# CM85F register map
Registers are read-write, no defined reset value unless marked. A register's access mark holds for its fields unless they carry their own. Offsets are from the block's base; [hi:lo] are bit positions; {n}, {i} and the like mark numbered series; 'fields as' and 'values as' point back to an identical list.

## MSC — Memory System Control Registers
Base 0xE001E000
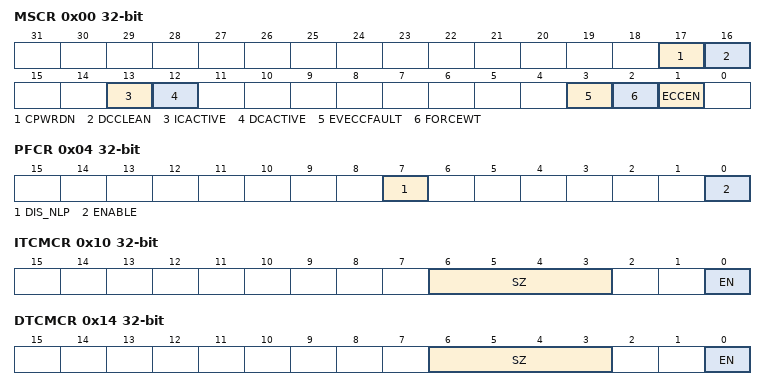
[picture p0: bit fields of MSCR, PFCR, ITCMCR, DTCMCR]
0x00 MSCR — Memory System Control Register controls the memory system features specific to the processor
  [17] CPWRDN — Indicates when the data and instruction caches are not accessible because they are either being powered down or being initialized using the automatic invalidation sequence
    0=Data and instruction cache is in normal operational state; 1=Data and instruction cacheis powered down or automatic invalidation sequence is in process
  [16] DCCLEAN — Indicates whether the data cache contains any dirty lines
    0=Level 1 (L1) data cache contains at least one dirty line; 1=L1 data cache does not contain any dirty lines
  [13] ICACTIVE — Indicates whether the L1 instruction cache is active
    0=L1 instruction cache is inactive; 1=L1 instruction cache is active
  [12] DCACTIVE — Indicates whether the L1 data cache is active
    0=L1 data cache is inactive; 1=L1 data cache is active
  [3] EVECCFAULT — Enables asynchronous BusFault exceptions when data is lost on evictions
    0=Asynchronous BusFaults are not generated when evicting lines with multi-bit errors in the data; 1=Asynchronous aborts are generated when evicting lines with multi-errors in the data
  [2] FORCEWT — Enables Forced Write-Through in the L1 data cache
    0=Force Write-Through is disabled; 1=Force Write-Through is enabled
  [1] ECCEN — Indicates whether Error Correcting Code (ECC) is present and enabled
    0=ECC not present or not enabled; 1=ECC present and enabled
0x04 PFCR — Prefetcher Control Register controls the prefetcher
  [7] DIS_NLP — Disables Next Line Prefetch mode
    0=Next Line Prefetch is enabled; 1=Next Line Prefetch is disabled
  [0] ENABLE — Prefetcher enable
    0=Prefetcher is disabled; 1=Prefetcher is enabled
0x10 ITCMCR — ITCM Control Register enable access to the Tightly Coupled Memories (TCMs) by software running on the processor
  [6:3] SZ — Indicates the size of the relevant TCM
    0=No TCM implemented; 3=4KB; 4=8KB; 5=16KB; 6=32KB; 7=64KB; 8=128KB; 9=256KB; 10=512KB; 11=1MB; 12=2MB; 13=4MB; 14=8MB; 15=16MB
  [0] EN — TCM enable
    0=TCM disabled; 1=TCM enabled
0x14 DTCMCR — DTCM Control Register enable access to the Tightly Coupled Memories (TCMs) by software running on the processor
  fields as ITCMCR
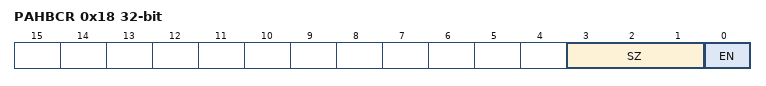
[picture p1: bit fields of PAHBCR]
0x18 PAHBCR — P-AHB Control Register enables accesses to Peripheral AHB (P-AHB) interface from software running on the processor
  [3:1] SZ — P-AHB size
    0=0MB. This implies that P-AHB disabled.; 1=64MB; 2=128MB; 3=256MB; 4=512MB
  [0] EN — P-AHB enable
    0=P-AHB disabled; 1=P-AHB enabled

## DCA — Direct Cache Access
Base 0xE001E200
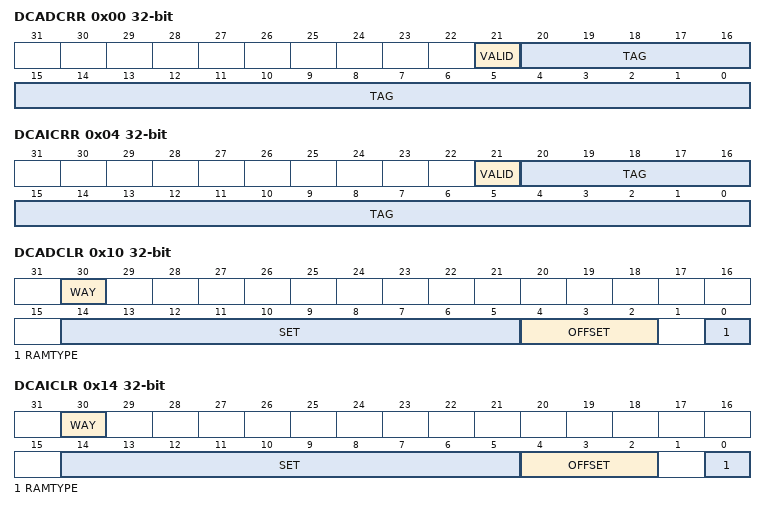
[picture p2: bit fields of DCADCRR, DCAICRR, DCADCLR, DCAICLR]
0x00 DCADCRR ro — Direct Data Cache Access Read Registers read the data from the Level 1 (L1) data cache from the location that is determined by the DCADCLR registers
  [21] VALID — Valid state of the cache line
  [20:0] TAG — Tag address. The number of significant bits of TAG depends on the cache size.
0x04 DCAICRR ro — Direct Instruction Cache Access Read Registers read the data from the Level 1 (L1) instruction cache from the location that is determined by the DCAICLR registers
  fields as DCADCRR
0x10 DCADCLR — Direct Data Cache Access Location Registers set the location to be read from the Level 1 (L1) data cache
  [30] WAY — Cache way
  [14:5] SET — Set index. The number of significant bits of SET depends on the cache size.
  [4:2] OFFSET — Data offset
  [0] RAMTYPE
    0=Tag RAM; 1=Data RAM
0x14 DCAICLR — Direct Instruction Cache Access Location Registers set the location to be read from the Level 1 (L1) instruction cache
  fields as DCADCLR

## ERRBNK — Implementation defined error banking
Base 0xE001E100
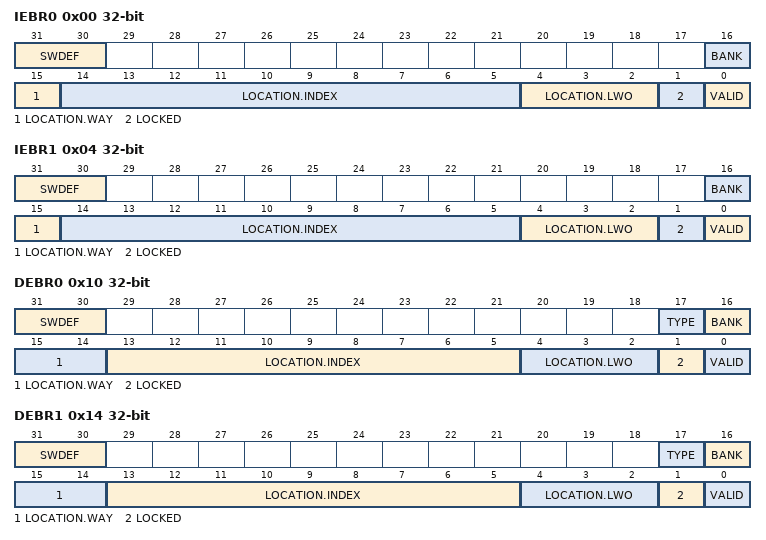
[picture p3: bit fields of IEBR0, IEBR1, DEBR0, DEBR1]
0x00 IEBR0 — Instruction Cache Error Bank Register record errors that occur during memory accesses to the L1 instruction cache
  [31:30] SWDEF — Error detection logic sets this field to 0b00 on a new allocation and on Cold reset
  [16] BANK — Indicates which RAM bank to use
    0=Tag RAM; 1=Data RAM
  [15] LOCATION.WAY — Indicates the location in the L1 instruction cache RAM, way
  [14:5] LOCATION.INDEX — Indicates the location in the L1 instruction cache RAM, index
  [4:2] LOCATION.LWO — Indicates the location in the L1 instruction cache RAM, line word offset
  [1] LOCKED — Indicates whether the location is locked or not
    0=Location is not locked and available for hardware to allocate; 1=Software has locked the location and hardware is not allowed to allocate to this entry
  [0] VALID — Indicates whether the entry is valid or not
    0=Entry is invalid; 1=Entry is valid
0x04 IEBR1 — Instruction Cache Error Bank Register record errors that occur during memory accesses to the L1 instruction cache
  fields as IEBR0
0x10 DEBR0 — Data Cache Error Bank Register record errors that occur during memory accesses to the L1 data cache
  [31:30] SWDEF — Error detection logic sets this field to 0b00 on a new allocation and on Cold reset
  [17] TYPE — Indicates the error type
    0=Single-bit error; 1=Multi-bit error
  [16] BANK — Indicates which RAM bank to use
    0=Tag RAM; 1=Data RAM
  [15:14] LOCATION.WAY — Indicates the location in the L1 instruction cache RAM, way
  [13:5] LOCATION.INDEX — Indicates the location in the L1 instruction cache RAM, index
  [4:2] LOCATION.LWO — Indicates the location in the L1 instruction cache RAM, line doubleword offset
  [1] LOCKED — Indicates whether the location is locked or not
    values as IEBR0.LOCKED
  [0] VALID — Indicates whether the entry is valid or not
    0=Entry is invalid; 1=Entry is valid
0x14 DEBR1 — Data Cache Error Bank Register record errors that occur during memory accesses to the L1 data cache
  fields as DEBR0
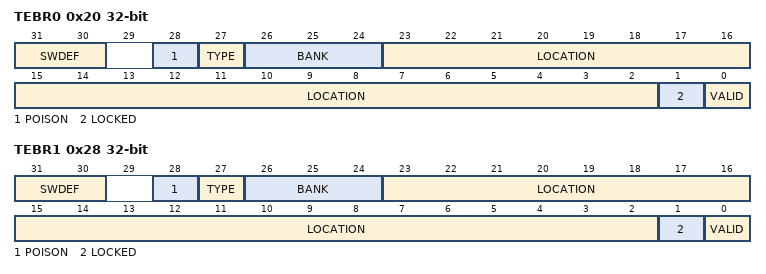
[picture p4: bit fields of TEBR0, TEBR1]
0x20 TEBR0 — TCM Error Bank Register record the location of errors in the TCM
  [31:30] SWDEF — Error detection logic sets this field to 0b00 on a new allocation and on Cold reset
  [28] POISON — Indicates whether a BusFault is generated or not
    0=Load or non-word store to an address that hits this TEBR gets a BusFault; 1=Load or non-word store to an address that hits this TEBR accesses the corresponding TEBRDATA register and does not get a BusFault
  [27] TYPE — Indicates the error type
    0=Single-bit error; 1=Multi-bit error
  [26:24] BANK — Indicates which RAM bank to use
    {v}=DTCM{v} (v=0..3); 4=ITCM
  [23:2] LOCATION — Indicates the physical location in the data cache RAM
  [1] LOCKED — Indicates whether the location is locked or not
    values as IEBR0.LOCKED
  [0] VALID — Indicates whether the entry is valid or not
    0=Entry is invalid; 1=Entry is valid
0x28 TEBR1 — TCM Error Bank Register 1 record the location of errors in the TCM
  fields as TEBR0
